# SN32F760 register map
Vendor: SONiX Technology Co., Ltd.; Series: SN32F760; File version: 2.0
CPU: CM0 r0p0, little endian, no MPU, no FPU, 2 interrupt priority bits
Registers are 32-bit, read-write, reset 0x0 unless marked. A register's access mark holds for its fields unless they carry their own. Offsets are from the block's base; [hi:lo] are bit positions.

## SN_PFPA — Peripheral Function Pin Assignment
Base 0x40042000
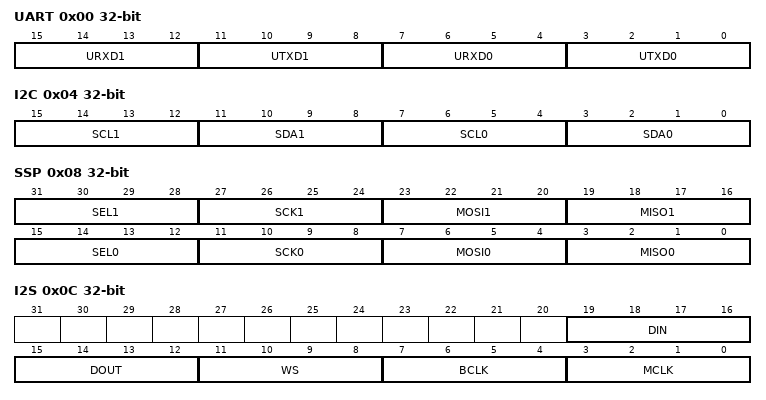
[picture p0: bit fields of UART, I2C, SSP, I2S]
0x00 UART — Offset:0x00 PFPA for UART Register
  [15:12] URXD1 — URXD1 assigned pin
    0=P1.0 (URXD1=P1.0); 1=P0.7 (URXD1=P0.7); 2=P0.12 (URXD1=P0.12); 3=P1.5 (URXD1=P1.5); 4=P1.13 (URXD1=P1.13); 5=P1.15 (URXD1=P1.15); 6=P3.6 (URXD1=P3.6); 7=P3.12 (URXD1=P3.12)
  [11:8] UTXD1 — UTXD1 assigned pin
    0=P1.1 (UTXD1=P1.1); 1=P0.6 (UTXD1=P0.6); 2=P0.13 (UTXD1=P0.13); 3=P1.4 (UTXD1=P1.4); 4=P1.14 (UTXD1=P1.14); 5=P3.8 (UTXD1=P3.8); 6=P3.10 (UTXD1=P3.10); 7=P3.13 (UTXD1=P3.13)
  [7:4] URXD0 — URXD0 assigned pin
    0=P0.0 (URXD0=P0.0); 1=P0.4 (URXD0=P0.4); 2=P1.3 (URXD0=P1.3); 3=P3.0 (URXD0=P3.0); 4=P3.3 (URXD0=P3.3); 5=P3.5 (URXD0=P3.5); 6=P3.11 (URXD0=P3.11); 7=P3.14 (URXD0=P3.14)
  [3:0] UTXD0 — UTXD0 assigned pin
    0=P0.1 (UTXD0=P0.1); 1=P0.5 (UTXD0=P0.5); 2=P1.2 (UTXD0=P1.2); 3=P3.1 (UTXD0=P3.1); 4=P3.2 (UTXD0=P3.2); 5=P3.4 (UTXD0=P3.4); 6=P3.10 (UTXD0=P3.10); 7=P3.15 (UTXD0=P3.15)
0x04 I2C — Offset:0x04 PFPA for I2C Register
  [15:12] SCL1 — SCL1 assigned pin
    0=P0.6 (SCL1=P0.6); 1=P0.0 (SCL1=P0.0); 2=P1.1 (SCL1=P1.1); 3=P1.9 (SCL1=P1.9); 4=P3.0 (SCL1=P3.0); 5=P3.3 (SCL1=P3.3); 6=P3.6 (SCL1=P3.6); 7=P3.13 (SCL1=P3.13)
  [11:8] SDA1 — SDA1 assigned pin
    0=P0.7 (SDA1=P0.7); 1=P0.1 (SDA1=P0.1); 2=P1.0 (SDA1=P1.0); 3=P1.8 (SDA1=P1.8); 4=P3.2 (SDA1=P3.2); 5=P3.4 (SDA1=P3.4); 6=P3.5 (SDA1=P3.5); 7=P3.12 (SDA1=P3.12)
  [7:4] SCL0 — SCL0 assigned pin
    0=P1.5 (SCL0=P1.5); 1=P0.2 (SCL0=P0.2); 2=P0.15 (SCL0=P0.15); 3=P1.3 (SCL0=P1.3); 4=P1.14 (SCL0=P1.14); 5=P3.9 (SCL0=P3.9); 6=P3.11 (SCL0=P3.11); 7=P3.14 (SCL0=P3.14)
  [3:0] SDA0 — SDA0 assigned pin
    0=P1.4 (SDA0=P1.4); 1=P0.3 (SDA0=P0.3); 2=P0.10 (SDA0=P0.10); 3=P1.2 (SDA0=P1.2); 4=P1.13 (SDA0=P1.13); 5=P3.7 (SDA0=P3.7); 6=P3.13 (SDA0=P3.13); 7=P3.15 (SDA0=P3.15)
0x08 SSP — Offset:0x08 PFPA for SSP Register
  [31:28] SEL1 — SEL1 assigned pin
    0=P3.6 (SEL1=P3.6); 1=P0.2 (SEL1=P0.2); 2=P0.13 (SEL1=P0.13); 3=P1.0 (SEL1=P1.0); 4=P1.4 (SEL1=P1.4); 5=P1.7 (SEL1=P1.7); 6=P1.14 (SEL1=P1.14); 7=P3.11 (SEL1=P3.11); 8=P2.1 (SEL1=P2.1); 9=P2.14 (SEL1=P2.14)
  [27:24] SCK1 — SCK1 assigned pin
    0=P3.7 (SCK1=P3.7); 1=P0.7 (SCK1=P0.7); 2=P0.14 (SCK1=P0.14); 3=P1.1 (SCK1=P1.1); 4=P1.11 (SCK1=P1.11); 5=P1.15 (SCK1=P1.15); 6=P3.3 (SCK1=P3.3); 7=P3.14 (SCK1=P3.14); 8=P2.2 (SCK1=P2.2); 9=P2.13 (SCK1=P2.13)
  [23:20] MOSI1 — MOSI1 assigned pin
    0=P3.8 (MOSI1=P3.8); 1=P0.5 (MOSI1=P0.5); 2=P0.12 (MOSI1=P0.12); 3=P1.2 (MOSI1=P1.2); 4=P1.6 (MOSI1=P1.6); 5=P1.13 (MOSI1=P1.13); 6=P3.2 (MOSI1=P3.2); 7=P3.13 (MOSI1=P3.13); 8=P2.0 (MOSI1=P2.0); 9=P2.15 (MOSI1=P2.15)
  [19:16] MISO1 — MISO1 assigned pin
    0=P3.9 (MISO1=P3.9); 1=P0.4 (MISO1=P0.4); 2=P0.10 (MISO1=P0.10); 3=P1.3 (MISO1=P1.3); 4=P1.10 (MISO1=P1.10); 5=P3.0 (MISO1=P3.0); 6=P3.4 (MISO1=P3.4); 7=P3.12 (MISO1=P3.12); 8=P2.1 (MISO1=P2.1); 9=P2.12 (MISO1=P2.12)
  [15:12] SEL0 — SEL0 assigned pin
    0=P0.5 (SEL0=P0.5); 1=P0.10 (SEL0=P0.10); 2=P0.12 (SEL0=P0.12); 3=P1.5 (SEL0=P1.5); 4=P1.11 (SEL0=P1.11); 5=P3.1 (SEL0=P3.1); 6=P3.5 (SEL0=P3.5); 7=P3.10 (SEL0=P3.10); 8=P2.0 (SEL0=P2.0); 9=P2.15 (SEL0=P2.15)
  [11:8] SCK0 — SCK0 assigned pin
    0=P0.4 (SCK0=P0.4); 1=P0.11 (SCK0=P0.11); 2=P0.13 (SCK0=P0.13); 3=P1.4 (SCK0=P1.4); 4=P1.12 (SCK0=P1.12); 5=P3.2 (SCK0=P3.2); 6=P3.6 (SCK0=P3.6); 7=P3.11 (SCK0=P3.11); 8=P2.3 (SCK0=P2.3); 9=P2.14 (SCK0=P2.14)
  [7:4] MOSI0 — MOSI0 assigned pin
    0=P0.3 (MOSI0=P0.3); 1=P0.1 (MOSI0=P0.1); 2=P0.7 (MOSI0=P0.7); 3=P0.14 (MOSI0=P0.14); 4=P1.1 (MOSI0=P1.1); 5=P1.15 (MOSI0=P1.15); 6=P3.4 (MOSI0=P3.4); 7=P3.14 (MOSI0=P3.14); 8=P2.2 (MOSI0=P2.2); 9=P2.13 (MOSI0=P2.13)
  [3:0] MISO0 — MISO0 assigned pin
    0=P0.2 (MISO0=P0.2); 1=P0.0 (MISO0=P0.0); 2=P0.6 (MISO0=P0.6); 3=P0.15 (MISO0=P0.15); 4=P1.0 (MISO0=P1.0); 5=P1.14 (MISO0=P1.14); 6=P3.3 (MISO0=P3.3); 7=P3.15 (MISO0=P3.15); 8=P2.1 (MISO0=P2.1); 9=P2.12 (MISO0=P2.12)
0x0C I2S — Offset:0x0C PFPA for I2S Register
  [19:16] DIN — I2SDIN assigned pin
    0=P3.0 (DIN=P3.0); 1=P0.10 (DIN=P0.10); 2=P1.6 (DIN=P1.6); 3=P3.9 (DIN=P3.9); 4=P2.0 (DIN=P2.0); 5=P2.5 (DIN=P2.5)
  [15:12] DOUT — I2SDOUT assigned pin
    0=P3.1 (DOUT=P3.1); 1=P0.11 (DOUT=P0.11); 2=P1.7 (DOUT=P1.7); 3=P3.8 (DOUT=P3.8); 4=P2.8 (DOUT=P2.8); 5=P2.12 (DOUT=P2.12)
  [11:8] WS — I2SWS assigned pin
    0=P3.4 (WS=P3.4); 1=P0.14 (WS=P0.14); 2=P1.10 (WS=P1.10); 3=P2.1 (WS=P2.1); 4=P2.7 (WS=P2.7); 5=P2.9 (WS=P2.9)
  [7:4] BCLK — I2SBCLK assigned pin
    0=P3.3 (BCLK=P3.3); 1=P0.13 (BCLK=P0.13); 2=P1.9 (BCLK=P1.9); 3=P3.6 (BCLK=P3.6); 4=P2.10 (BCLK=P2.10); 5=P2.11 (BCLK=P2.11)
  [3:0] MCLK — I2SMCLK assigned pin
    0=P3.2 (MCLK=P3.2); 1=P0.12 (MCLK=P0.12); 2=P1.8 (MCLK=P1.8); 3=P3.7 (MCLK=P3.7); 4=P2.2 (MCLK=P2.2); 5=P2.6 (MCLK=P2.6)
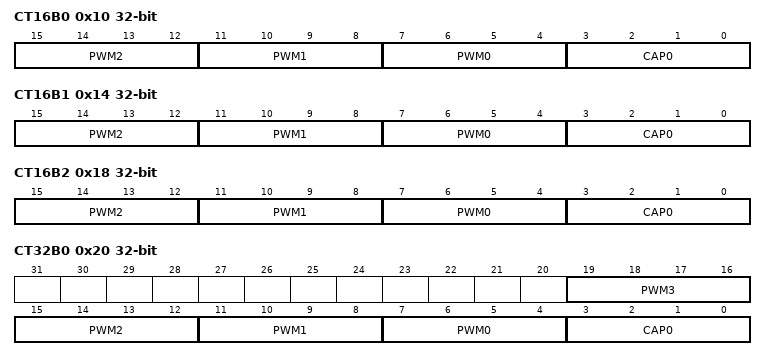
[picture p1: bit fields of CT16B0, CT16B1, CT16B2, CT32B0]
0x10 CT16B0 — Offset:0x10 PFPA for CT16B0 Register
  [15:12] PWM2 — CT16B0_PWM2 assigned pin
    0=P1.12 (CT16B0_PWM2=P1.12); 1=P0.9 (CT16B0_PWM2=P0.9); 2=P0.11 (CT16B0_PWM2=P0.11); 3=P1.6 (CT16B0_PWM2=P1.6); 4=P3.6 (CT16B0_PWM2=P3.6); 5=P3.15 (CT16B0_PWM2=P3.15); 6=P2.4 (CT16B0_PWM2=P2.4); 7=P2.10 (CT16B0_PWM2=P2.10)
  [11:8] PWM1 — CT16B0_PWM1 assigned pin
    0=P0.1 (CT16B0_PWM1=P0.1); 1=P0.4 (CT16B0_PWM1=P0.4); 2=P0.10 (CT16B0_PWM1=P0.10); 3=P1.13 (CT16B0_PWM1=P1.13); 4=P3.4 (CT16B0_PWM1=P3.4); 5=P3.12 (CT16B0_PWM1=P3.12); 6=P2.2 (CT16B0_PWM1=P2.2); 7=P2.11 (CT16B0_PWM1=P2.11)
  [7:4] PWM0 — CT16B0_PWM0 assigned pin
    0=P0.0 (CT16B0_PWM0=P0.0); 1=P1.1 (CT16B0_PWM0=P1.1); 2=P1.8 (CT16B0_PWM0=P1.8); 3=P1.12 (CT16B0_PWM0=P1.12); 4=P3.3 (CT16B0_PWM0=P3.3); 5=P3.11 (CT16B0_PWM0=P3.11); 6=P2.3 (CT16B0_PWM0=P2.3); 7=P2.15 (CT16B0_PWM0=P2.15)
  [3:0] CAP0 — CT16B0_CAP0 assigned pin
    0=P0.2 (CT16B0_CAP0=P0.2); 1=P0.8 (CT16B0_CAP0=P0.8); 2=P1.0 (CT16B0_CAP0=P1.0); 3=P3.0 (CT16B0_CAP0=P3.0); 4=P3.2 (CT16B0_CAP0=P3.2); 5=P3.10 (CT16B0_CAP0=P3.10); 6=P2.0 (CT16B0_CAP0=P2.0); 7=P2.13 (CT16B0_CAP0=P2.13)
0x14 CT16B1 — Offset:0x14 PFPA for CT16B1 Register
  [15:12] PWM2 — CT16B1_PWM2 assigned pin
    0=P1.9 (CT16B1_PWM2=P1.9); 1=P0.6 (CT16B1_PWM2=P0.6); 2=P0.15 (CT16B1_PWM2=P0.15); 3=P1.2 (CT16B1_PWM2=P1.2); 4=P1.14 (CT16B1_PWM2=P1.14); 5=P3.8 (CT16B1_PWM2=P3.8); 6=P2.3 (CT16B1_PWM2=P2.3); 7=P2.7 (CT16B1_PWM2=P2.7)
  [11:8] PWM1 — CT16B1_PWM1 assigned pin
    0=P0.11 (CT16B1_PWM1=P0.11); 1=P0.8 (CT16B1_PWM1=P0.8); 2=P0.12 (CT16B1_PWM1=P0.12); 3=P1.3 (CT16B1_PWM1=P1.3); 4=P1.10 (CT16B1_PWM1=P1.10); 5=P3.9 (CT16B1_PWM1=P3.9); 6=P2.4 (CT16B1_PWM1=P2.4); 7=P2.8 (CT16B1_PWM1=P2.8)
  [7:4] PWM0 — CT16B1_PWM0 assigned pin
    0=P0.10 (CT16B1_PWM0=P0.10); 1=P0.5 (CT16B1_PWM0=P0.5); 2=P1.9 (CT16B1_PWM0=P1.9); 3=P1.15 (CT16B1_PWM0=P1.15); 4=P3.7 (CT16B1_PWM0=P3.7); 5=P3.14 (CT16B1_PWM0=P3.14); 6=P2.0 (CT16B1_PWM0=P2.0); 7=P2.12 (CT16B1_PWM0=P2.12)
  [3:0] CAP0 — CT16B1_CAP0 assigned pin
    0=P0.12 (CT16B1_CAP0=P0.12); 1=P0.7 (CT16B1_CAP0=P0.7); 2=P1.7 (CT16B1_CAP0=P1.7); 3=P1.11 (CT16B1_CAP0=P1.11); 4=P3.5 (CT16B1_CAP0=P3.5); 5=P3.13 (CT16B1_CAP0=P3.13); 6=P2.1 (CT16B1_CAP0=P2.1); 7=P2.9 (CT16B1_CAP0=P2.9)
0x18 CT16B2 — Offset:0x18 PFPA for CT16B2 Register
  [15:12] PWM2 — CT16B2_PWM2 assigned pin
    0=P3.1 (CT16B2_PWM2=P3.1); 1=P0.1 (CT16B2_PWM2=P0.1); 2=P1.0 (CT16B2_PWM2=P1.0); 3=P1.12 (CT16B2_PWM2=P1.12); 4=P3.0 (CT16B2_PWM2=P3.0); 5=P3.11 (CT16B2_PWM2=P3.11); 6=P2.4 (CT16B2_PWM2=P2.4); 7=P2.10 (CT16B2_PWM2=P2.10)
  [11:8] PWM1 — CT16B2_PWM1 assigned pin
    0=P1.4 (CT16B2_PWM1=P1.4); 1=P0.0 (CT16B2_PWM1=P0.0); 2=P0.9 (CT16B2_PWM1=P0.9); 3=P1.11 (CT16B2_PWM1=P1.11); 4=P3.5 (CT16B2_PWM1=P3.5); 5=P3.15 (CT16B2_PWM1=P3.15); 6=P2.1 (CT16B2_PWM1=P2.1); 7=P2.6 (CT16B2_PWM1=P2.6)
  [7:4] PWM0 — CT16B2_PWM0 assigned pin
    0=P3.5 (CT16B2_PWM0=P3.5); 1=P0.2 (CT16B2_PWM0=P0.2); 2=P0.14 (CT16B2_PWM0=P0.14); 3=P1.4 (CT16B2_PWM0=P1.4); 4=P3.1 (CT16B2_PWM0=P3.1); 5=P3.10 (CT16B2_PWM0=P3.10); 6=P2.5 (CT16B2_PWM0=P2.5); 7=P2.9 (CT16B2_PWM0=P2.9)
  [3:0] CAP0 — CT16B2_CAP0 assigned pin
    0=P1.8 (CT16B2_CAP0=P1.8); 1=P0.3 (CT16B2_CAP0=P0.3); 2=P0.13 (CT16B2_CAP0=P0.13); 3=P1.5 (CT16B2_CAP0=P1.5); 4=P3.6 (CT16B2_CAP0=P3.6); 5=P3.12 (CT16B2_CAP0=P3.12); 6=P2.2 (CT16B2_CAP0=P2.2); 7=P2.14 (CT16B2_CAP0=P2.14)
0x20 CT32B0 — Offset:0x20 PFPA for CT32B0 Register
  [19:16] PWM3 — CT32B0_PWM3 assigned pin
    0=P1.2 (CT32B0_PWM3=P1.2); 1=P0.3 (CT32B0_PWM3=P0.3); 2=P0.7 (CT32B0_PWM3=P0.7); 3=P0.15 (CT32B0_PWM3=P0.15); 4=P1.12 (CT32B0_PWM3=P1.12); 5=P3.4 (CT32B0_PWM3=P3.4); 6=P2.2 (CT32B0_PWM3=P2.2); 7=P2.12 (CT32B0_PWM3=P2.12)
  [15:12] PWM2 — CT32B0_PWM2 assigned pin
    0=P1.14 (CT32B0_PWM2=P1.14); 1=P0.5 (CT32B0_PWM2=P0.5); 2=P0.9 (CT32B0_PWM2=P0.9); 3=P1.9 (CT32B0_PWM2=P1.9); 4=P3.7 (CT32B0_PWM2=P3.7); 5=P3.13 (CT32B0_PWM2=P3.13); 6=P2.0 (CT32B0_PWM2=P2.0); 7=P2.11 (CT32B0_PWM2=P2.11)
  [11:8] PWM1 — CT32B0_PWM1 assigned pin
    0=P3.8 (CT32B0_PWM1=P3.8); 1=P0.8 (CT32B0_PWM1=P0.8); 2=P0.14 (CT32B0_PWM1=P0.14); 3=P1.5 (CT32B0_PWM1=P1.5); 4=P1.11 (CT32B0_PWM1=P1.11); 5=P3.14 (CT32B0_PWM1=P3.14); 6=P2.4 (CT32B0_PWM1=P2.4); 7=P2.13 (CT32B0_PWM1=P2.13)
  [7:4] PWM0 — CT32B0_PWM0 assigned pin
    0=P1.15 (CT32B0_PWM0=P1.15); 1=P0.4 (CT32B0_PWM0=P0.4); 2=P0.11 (CT32B0_PWM0=P0.11); 3=P1.8 (CT32B0_PWM0=P1.8); 4=P1.14 (CT32B0_PWM0=P1.14); 5=P3.9 (CT32B0_PWM0=P3.9); 6=P2.3 (CT32B0_PWM0=P2.3); 7=P2.14 (CT32B0_PWM0=P2.14)
  [3:0] CAP0 — CT32B0_CAP0 assigned pin
    0=P3.9 (CT32B0_CAP0=P3.9); 1=P0.0 (CT32B0_CAP0=P0.0); 2=P0.9 (CT32B0_CAP0=P0.9); 3=P1.1 (CT32B0_CAP0=P1.1); 4=P3.1 (CT32B0_CAP0=P3.1); 5=P3.3 (CT32B0_CAP0=P3.3); 6=P2.3 (CT32B0_CAP0=P2.3); 7=P2.15 (CT32B0_CAP0=P2.15)
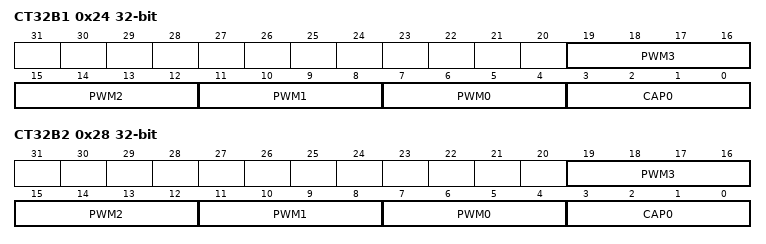
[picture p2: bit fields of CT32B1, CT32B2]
0x24 CT32B1 — Offset:0x24 PFPA for CT32B1 Register
  [19:16] PWM3 — CT32B1_PWM3 assigned pin
    0=P1.7 (CT32B1_PWM3=P1.7); 1=P0.6 (CT32B1_PWM3=P0.6); 2=P0.7 (CT32B1_PWM3=P0.7); 3=P1.2 (CT32B1_PWM3=P1.2); 4=P3.9 (CT32B1_PWM3=P3.9); 5=P3.11 (CT32B1_PWM3=P3.11); 6=P2.4 (CT32B1_PWM3=P2.4); 7=P2.13 (CT32B1_PWM3=P2.13)
  [15:12] PWM2 — CT32B1_PWM2 assigned pin
    0=P1.6 (CT32B1_PWM2=P1.6); 1=P0.5 (CT32B1_PWM2=P0.5); 2=P0.8 (CT32B1_PWM2=P0.8); 3=P0.11 (CT32B1_PWM2=P0.11); 4=P3.12 (CT32B1_PWM2=P3.12); 5=P2.5 (CT32B1_PWM2=P2.5); 6=P2.12 (CT32B1_PWM2=P2.12); 7=P2.14 (CT32B1_PWM2=P2.14)
  [11:8] PWM1 — CT32B1_PWM1 assigned pin
    0=P0.15 (CT32B1_PWM1=P0.15); 1=P0.4 (CT32B1_PWM1=P0.4); 2=P1.2 (CT32B1_PWM1=P1.2); 3=P1.10 (CT32B1_PWM1=P1.10); 4=P3.5 (CT32B1_PWM1=P3.5); 5=P3.10 (CT32B1_PWM1=P3.10); 6=P2.1 (CT32B1_PWM1=P2.1); 7=P2.8 (CT32B1_PWM1=P2.8)
  [7:4] PWM0 — CT32B1_PWM0 assigned pin
    0=P1.13 (CT32B1_PWM0=P1.13); 1=P0.1 (CT32B1_PWM0=P0.1); 2=P0.9 (CT32B1_PWM0=P0.9); 3=P1.3 (CT32B1_PWM0=P1.3); 4=P3.2 (CT32B1_PWM0=P3.2); 5=P3.15 (CT32B1_PWM0=P3.15); 6=P2.6 (CT32B1_PWM0=P2.6); 7=P2.15 (CT32B1_PWM0=P2.15)
  [3:0] CAP0 — CT32B1_CAP0 assigned pin
    0=P1.3 (CT32B1_CAP0=P1.3); 1=P0.2 (CT32B1_CAP0=P0.2); 2=P0.8 (CT32B1_CAP0=P0.8); 3=P0.15 (CT32B1_CAP0=P0.15); 4=P1.6 (CT32B1_CAP0=P1.6); 5=P3.8 (CT32B1_CAP0=P3.8); 6=P2.4 (CT32B1_CAP0=P2.4); 7=P2.10 (CT32B1_CAP0=P2.10)
0x28 CT32B2 — Offset:0x28 PFPA for CT32B2 Register
  [19:16] PWM3 — CT32B2_PWM3 assigned pin
    0=P0.6 (CT32B2_PWM3=P0.6); 1=P1.0 (CT32B2_PWM3=P1.0); 2=P1.7 (CT32B2_PWM3=P1.7); 3=P3.10 (CT32B2_PWM3=P3.10); 4=P2.3 (CT32B2_PWM3=P2.3); 5=P2.8 (CT32B2_PWM3=P2.8); 6=P2.9 (CT32B2_PWM3=P2.9); 7=P2.15 (CT32B2_PWM3=P2.15)
  [15:12] PWM2 — CT32B2_PWM2 assigned pin
    0=P0.3 (CT32B2_PWM2=P0.3); 1=P0.0 (CT32B2_PWM2=P0.0); 2=P0.9 (CT32B2_PWM2=P0.9); 3=P1.6 (CT32B2_PWM2=P1.6); 4=P3.1 (CT32B2_PWM2=P3.1); 5=P3.13 (CT32B2_PWM2=P3.13); 6=P3.15 (CT32B2_PWM2=P3.15); 7=P2.14 (CT32B2_PWM2=P2.14)
  [11:8] PWM1 — CT32B2_PWM1 assigned pin
    0=P0.14 (CT32B2_PWM1=P0.14); 1=P0.2 (CT32B2_PWM1=P0.2); 2=P0.15 (CT32B2_PWM1=P0.15); 3=P1.5 (CT32B2_PWM1=P1.5); 4=P3.0 (CT32B2_PWM1=P3.0); 5=P3.7 (CT32B2_PWM1=P3.7); 6=P2.7 (CT32B2_PWM1=P2.7); 7=P2.13 (CT32B2_PWM1=P2.13)
  [7:4] PWM0 — CT32B2_PWM0 assigned pin
    0=P0.13 (CT32B2_PWM0=P0.13); 1=P0.3 (CT32B2_PWM0=P0.3); 2=P0.8 (CT32B2_PWM0=P0.8); 3=P1.1 (CT32B2_PWM0=P1.1); 4=P1.7 (CT32B2_PWM0=P1.7); 5=P1.15 (CT32B2_PWM0=P1.15); 6=P2.11 (CT32B2_PWM0=P2.11); 7=P2.15 (CT32B2_PWM0=P2.15)
  [3:0] CAP0 — CT32B2_CAP0 assigned pin
    0=P3.7 (CT32B2_CAP0=P3.7); 1=P0.9 (CT32B2_CAP0=P0.9); 2=P0.10 (CT32B2_CAP0=P0.10); 3=P1.4 (CT32B2_CAP0=P1.4); 4=P1.13 (CT32B2_CAP0=P1.13); 5=P3.14 (CT32B2_CAP0=P3.14); 6=P2.5 (CT32B2_CAP0=P2.5); 7=P2.12 (CT32B2_CAP0=P2.12)
